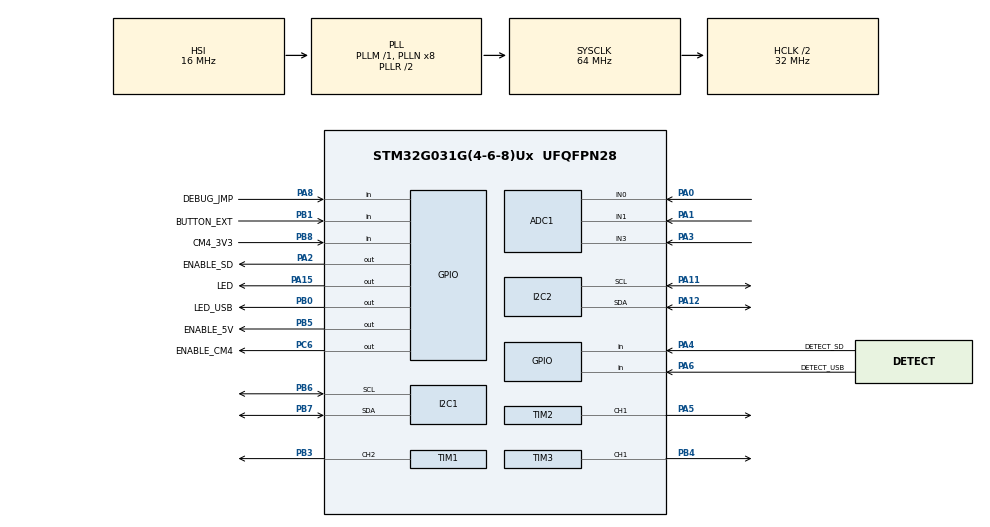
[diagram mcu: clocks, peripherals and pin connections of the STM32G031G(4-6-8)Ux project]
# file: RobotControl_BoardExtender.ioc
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ADC1.Channel-0\#ChannelRegularConversion=ADC_CHANNEL_1
ADC1.NbrOfConversionFlag=1
ADC1.Rank-0\#ChannelRegularConversion=1
ADC1.SamplingTime-0\#ChannelRegularConversion=ADC_SAMPLINGTIME_COMMON_1
ADC1.SelectedChannel=ADC_CHANNEL_0|ADC_CHANNEL_1|ADC_CHANNEL_3
ADC1.master=1
Dma.Request0=TIM3_CH1
Dma.Request1=TIM2_CH1
Dma.TIM2_CH1.1.Direction=DMA_MEMORY_TO_PERIPH
Dma.TIM2_CH1.1.EventEnable=DISABLE
Dma.TIM2_CH1.1.Instance=DMA1_Channel2
Dma.TIM2_CH1.1.MemDataAlignment=DMA_MDATAALIGN_BYTE
Dma.TIM2_CH1.1.MemInc=DMA_MINC_ENABLE
Dma.TIM2_CH1.1.Mode=DMA_NORMAL
Dma.TIM2_CH1.1.PeriphDataAlignment=DMA_PDATAALIGN_WORD
Dma.TIM2_CH1.1.PeriphInc=DMA_PINC_DISABLE
Dma.TIM2_CH1.1.Polarity=HAL_DMAMUX_REQ_GEN_RISING
Dma.TIM2_CH1.1.Priority=DMA_PRIORITY_LOW
Dma.TIM2_CH1.1.RequestNumber=1
Dma.TIM2_CH1.1.SignalID=NONE
Dma.TIM2_CH1.1.SyncEnable=DISABLE
Dma.TIM2_CH1.1.SyncPolarity=HAL_DMAMUX_SYNC_NO_EVENT
Dma.TIM2_CH1.1.SyncRequestNumber=1
Dma.TIM2_CH1.1.SyncSignalID=NONE
Dma.TIM3_CH1.0.Direction=DMA_MEMORY_TO_PERIPH
Dma.TIM3_CH1.0.EventEnable=DISABLE
Dma.TIM3_CH1.0.Instance=DMA1_Channel1
Dma.TIM3_CH1.0.MemDataAlignment=DMA_MDATAALIGN_BYTE
Dma.TIM3_CH1.0.MemInc=DMA_MINC_ENABLE
Dma.TIM3_CH1.0.Mode=DMA_NORMAL
Dma.TIM3_CH1.0.PeriphDataAlignment=DMA_PDATAALIGN_HALFWORD
Dma.TIM3_CH1.0.PeriphInc=DMA_PINC_DISABLE
Dma.TIM3_CH1.0.Polarity=HAL_DMAMUX_REQ_GEN_RISING
Dma.TIM3_CH1.0.Priority=DMA_PRIORITY_LOW
Dma.TIM3_CH1.0.RequestNumber=1
Dma.TIM3_CH1.0.SignalID=NONE
Dma.TIM3_CH1.0.SyncEnable=DISABLE
Dma.TIM3_CH1.0.SyncPolarity=HAL_DMAMUX_SYNC_NO_EVENT
Dma.TIM3_CH1.0.SyncRequestNumber=1
Dma.TIM3_CH1.0.SyncSignalID=NONE
I2C1.DualAddressMode=I2C_DUALADDRESS_ENABLE
I2C1.GeneralCallMode=I2C_GENERALCALL_DISABLE
I2C1.NoStretchMode=I2C_NOSTRETCH_DISABLE
I2C1.OwnAddress=0x01
I2C1.Timing=0x00707CBB
I2C2.OwnAddress=0x01
I2C2.Timing=0x00707CBB
Mcu.Family=STM32G0
Mcu.Name=STM32G031G(4-6-8)Ux
Mcu.Package=UFQFPN28
NVIC.DMA1_Channel1_IRQn=true\:0\:0\:false\:false\:true\:false\:true\:true
NVIC.DMA1_Channel2_3_IRQn=true\:0\:0\:false\:false\:true\:false\:true\:true
NVIC.I2C1_IRQn=true\:0\:0\:false\:false\:true\:true\:true\:true
NVIC.I2C2_IRQn=true\:0\:0\:false\:false\:true\:true\:true\:true
PA0.Mode=IN0
PA0.Signal=ADC1_IN0
PA1.Mode=IN1
PA1.Signal=ADC1_IN1
PA11\ [PA9].Mode=I2C
PA11\ [PA9].Signal=I2C2_SCL
PA12\ [PA10].Mode=I2C
PA12\ [PA10].Signal=I2C2_SDA
PA13.Mode=Serial_Wire
PA13.Signal=SYS_SWDIO
PA14-BOOT0.Mode=Serial_Wire
PA14-BOOT0.Signal=SYS_SWCLK
PA15.GPIO_Label=LED
PA15.Signal=GPIO_Output
PA2.GPIO_Label=ENABLE_SD
PA2.Signal=GPIO_Output
PA3.Mode=IN3
PA3.Signal=ADC1_IN3
PA4.GPIO_Label=DETECT_SD
PA4.Signal=GPIO_Input
PA5.GPIO_PuPd=GPIO_PULLDOWN
PA5.Signal=S_TIM2_CH1_ETR
PA6.GPIO_Label=DETECT_USB
PA6.GPIO_PuPd=GPIO_PULLUP
PA6.Signal=GPIO_Input
PA8.GPIO_Label=DEBUG_JMP
PA8.Signal=GPIO_Input
PB0.GPIO_Label=LED_USB
PB0.Signal=GPIO_Output
PB1.GPIO_Label=BUTTON_EXT
PB1.Signal=GPIO_Input
PB3.Signal=S_TIM1_CH2
PB4.Signal=S_TIM3_CH1
PB5.GPIO_Label=ENABLE_5V
PB5.Signal=GPIO_Output
PB6.Mode=I2C
PB6.Signal=I2C1_SCL
PB7.Mode=I2C
PB7.Signal=I2C1_SDA
PB8.GPIO_Label=CM4_3V3
PB8.Signal=GPIO_Input
PC6.GPIO_Label=ENABLE_CM4
PC6.GPIO_PuPd=GPIO_PULLDOWN
PC6.Signal=GPIO_Output
ProjectManager.HeapSize=0x200
ProjectManager.StackSize=0x400
ProjectManager.TargetToolchain=STM32CubeIDE
RCC.ADCFreq_Value=64000000
RCC.AHBCLKDivider=RCC_SYSCLK_DIV2
RCC.AHBFreq_Value=32000000
RCC.CortexFreq_Value=32000000
RCC.EXTERNAL_CLOCK_VALUE=12288000
RCC.HCLKFreq_Value=32000000
RCC.HSE_VALUE=8000000
RCC.HSI_VALUE=16000000
RCC.LSE_VALUE=32768
RCC.SYSCLKFreq_VALUE=64000000
RCC.SYSCLKSource=RCC_SYSCLKSOURCE_PLLCLK
RCC.VCOOutputFreq_Value=128000000
SH.S_TIM1_CH2.0=TIM1_CH2,PWM Generation2 CH2
SH.S_TIM2_CH1_ETR.0=TIM2_CH1,PWM Generation1 CH1
SH.S_TIM3_CH1.0=TIM3_CH1,PWM Generation1 CH1
TIM1.Channel-PWM\ Generation2\ CH2=TIM_CHANNEL_2
TIM1.Prescaler=5
TIM2.Channel-PWM\ Generation1\ CH1=TIM_CHANNEL_1
TIM2.Period=39
TIM3.Channel-PWM\ Generation1\ CH1=TIM_CHANNEL_1
TIM3.Period=39
board=custom

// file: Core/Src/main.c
/* USER CODE BEGIN Header */
/**
  ******************************************************************************
  * @file           : main.c
  * @brief          : Main program body
  ******************************************************************************
  * @attention
  *
  * Copyright (c) 2022 STMicroelectronics.
  * All rights reserved.
  *
  * This software is licensed under terms that can be found in the LICENSE file
  * in the root directory of this software component.
  * If no LICENSE file comes with this software, it is provided AS-IS.
  *
  ******************************************************************************
  */
/* USER CODE END Header */
#include "main.h"

ADC_HandleTypeDef hadc1;

I2C_HandleTypeDef hi2c1;
I2C_HandleTypeDef hi2c2;

TIM_HandleTypeDef htim1;
TIM_HandleTypeDef htim2;
TIM_HandleTypeDef htim3;
DMA_HandleTypeDef hdma_tim2_ch1;
DMA_HandleTypeDef hdma_tim3_ch1;

void SystemClock_Config(void);
static void MX_GPIO_Init(void);
static void MX_DMA_Init(void);
static void MX_ADC1_Init(void);
static void MX_I2C1_Init(void);
static void MX_TIM3_Init(void);
static void MX_TIM2_Init(void);
static void MX_TIM1_Init(void);
static void MX_I2C2_Init(void);

int main(void)
{

  /* MCU Configuration--------------------------------------------------------*/

  /* Reset of all peripherals, Initializes the Flash interface and the Systick. */
  HAL_Init();

  /* Configure the system clock */
  SystemClock_Config();

  /* Initialize all configured peripherals */
  MX_GPIO_Init();
  MX_DMA_Init();
  MX_ADC1_Init();
  MX_I2C1_Init();
  MX_TIM3_Init();
  MX_TIM2_Init();
  MX_TIM1_Init();
  MX_I2C2_Init();
  /* USER CODE BEGIN 2 */

  firmware_init();

  /* USER CODE END 2 */

  /* Infinite loop */
  while (1)
  {

    /* USER CODE BEGIN 3 */
	  firmware_update();
  }
  /* USER CODE END 3 */
}

void SystemClock_Config(void)
{
  RCC_OscInitTypeDef RCC_OscInitStruct = {0};
  RCC_ClkInitTypeDef RCC_ClkInitStruct = {0};

  /** Configure the main internal regulator output voltage
  */
  HAL_PWREx_ControlVoltageScaling(PWR_REGULATOR_VOLTAGE_SCALE1);

  /** Initializes the RCC Oscillators according to the specified parameters
  * in the RCC_OscInitTypeDef structure.
  */
  RCC_OscInitStruct.OscillatorType = RCC_OSCILLATORTYPE_HSI;
  RCC_OscInitStruct.HSIState = RCC_HSI_ON;
  RCC_OscInitStruct.HSIDiv = RCC_HSI_DIV1;
  RCC_OscInitStruct.HSICalibrationValue = RCC_HSICALIBRATION_DEFAULT;
  RCC_OscInitStruct.PLL.PLLState = RCC_PLL_ON;
  RCC_OscInitStruct.PLL.PLLSource = RCC_PLLSOURCE_HSI;
  RCC_OscInitStruct.PLL.PLLM = RCC_PLLM_DIV1;
  RCC_OscInitStruct.PLL.PLLN = 8;
  RCC_OscInitStruct.PLL.PLLP = RCC_PLLP_DIV2;
  RCC_OscInitStruct.PLL.PLLQ = RCC_PLLQ_DIV2;
  RCC_OscInitStruct.PLL.PLLR = RCC_PLLR_DIV2;
  if (HAL_RCC_OscConfig(&RCC_OscInitStruct) != HAL_OK)
  {
    Error_Handler();
  }

  /** Initializes the CPU, AHB and APB buses clocks
  */
  RCC_ClkInitStruct.ClockType = RCC_CLOCKTYPE_HCLK|RCC_CLOCKTYPE_SYSCLK
                              |RCC_CLOCKTYPE_PCLK1;
  RCC_ClkInitStruct.SYSCLKSource = RCC_SYSCLKSOURCE_PLLCLK;
  RCC_ClkInitStruct.AHBCLKDivider = RCC_SYSCLK_DIV2;
  RCC_ClkInitStruct.APB1CLKDivider = RCC_HCLK_DIV1;

  if (HAL_RCC_ClockConfig(&RCC_ClkInitStruct, FLASH_LATENCY_1) != HAL_OK)
  {
    Error_Handler();
  }
}

static void MX_ADC1_Init(void)
{

  ADC_ChannelConfTypeDef sConfig = {0};

  /** Configure the global features of the ADC (Clock, Resolution, Data Alignment and number of conversion)
  */
  hadc1.Instance = ADC1;
  hadc1.Init.ClockPrescaler = ADC_CLOCK_SYNC_PCLK_DIV2;
  hadc1.Init.Resolution = ADC_RESOLUTION_12B;
  hadc1.Init.DataAlign = ADC_DATAALIGN_RIGHT;
  hadc1.Init.ScanConvMode = ADC_SCAN_DISABLE;
  hadc1.Init.EOCSelection = ADC_EOC_SINGLE_CONV;
  hadc1.Init.LowPowerAutoWait = DISABLE;
  hadc1.Init.LowPowerAutoPowerOff = DISABLE;
  hadc1.Init.ContinuousConvMode = DISABLE;
  hadc1.Init.NbrOfConversion = 1;
  hadc1.Init.DiscontinuousConvMode = DISABLE;
  hadc1.Init.ExternalTrigConv = ADC_SOFTWARE_START;
  hadc1.Init.ExternalTrigConvEdge = ADC_EXTERNALTRIGCONVEDGE_NONE;
  hadc1.Init.DMAContinuousRequests = DISABLE;
  hadc1.Init.Overrun = ADC_OVR_DATA_PRESERVED;
  hadc1.Init.SamplingTimeCommon1 = ADC_SAMPLETIME_1CYCLE_5;
  hadc1.Init.SamplingTimeCommon2 = ADC_SAMPLETIME_1CYCLE_5;
  hadc1.Init.OversamplingMode = DISABLE;
  hadc1.Init.TriggerFrequencyMode = ADC_TRIGGER_FREQ_HIGH;
  if (HAL_ADC_Init(&hadc1) != HAL_OK)
  {
    Error_Handler();
  }

  /** Configure Regular Channel
  */
  sConfig.Channel = ADC_CHANNEL_1;
  sConfig.Rank = ADC_REGULAR_RANK_1;
  sConfig.SamplingTime = ADC_SAMPLINGTIME_COMMON_1;
  if (HAL_ADC_ConfigChannel(&hadc1, &sConfig) != HAL_OK)
  {
    Error_Handler();
  }

}

static void MX_I2C1_Init(void)
{

  hi2c1.Instance = I2C1;
  hi2c1.Init.Timing = 0x00707CBB;
  hi2c1.Init.OwnAddress1 = 2;
  hi2c1.Init.AddressingMode = I2C_ADDRESSINGMODE_7BIT;
  hi2c1.Init.DualAddressMode = I2C_DUALADDRESS_ENABLE;
  hi2c1.Init.OwnAddress2 = 0;
  hi2c1.Init.OwnAddress2Masks = I2C_OA2_NOMASK;
  hi2c1.Init.GeneralCallMode = I2C_GENERALCALL_DISABLE;
  hi2c1.Init.NoStretchMode = I2C_NOSTRETCH_DISABLE;
  if (HAL_I2C_Init(&hi2c1) != HAL_OK)
  {
    Error_Handler();
  }

  /** Configure Analogue filter
  */
  if (HAL_I2CEx_ConfigAnalogFilter(&hi2c1, I2C_ANALOGFILTER_ENABLE) != HAL_OK)
  {
    Error_Handler();
  }

  /** Configure Digital filter
  */
  if (HAL_I2CEx_ConfigDigitalFilter(&hi2c1, 0) != HAL_OK)
  {
    Error_Handler();
  }

}

static void MX_I2C2_Init(void)
{

  hi2c2.Instance = I2C2;
  hi2c2.Init.Timing = 0x00707CBB;
  hi2c2.Init.OwnAddress1 = 2;
  hi2c2.Init.AddressingMode = I2C_ADDRESSINGMODE_7BIT;
  hi2c2.Init.DualAddressMode = I2C_DUALADDRESS_DISABLE;
  hi2c2.Init.OwnAddress2 = 0;
  hi2c2.Init.OwnAddress2Masks = I2C_OA2_NOMASK;
  hi2c2.Init.GeneralCallMode = I2C_GENERALCALL_DISABLE;
  hi2c2.Init.NoStretchMode = I2C_NOSTRETCH_DISABLE;
  if (HAL_I2C_Init(&hi2c2) != HAL_OK)
  {
    Error_Handler();
  }

  /** Configure Analogue filter
  */
  if (HAL_I2CEx_ConfigAnalogFilter(&hi2c2, I2C_ANALOGFILTER_ENABLE) != HAL_OK)
  {
    Error_Handler();
  }

  /** Configure Digital filter
  */
  if (HAL_I2CEx_ConfigDigitalFilter(&hi2c2, 0) != HAL_OK)
  {
    Error_Handler();
  }

}

static void MX_TIM1_Init(void)
{

  TIM_MasterConfigTypeDef sMasterConfig = {0};
  TIM_OC_InitTypeDef sConfigOC = {0};
  TIM_BreakDeadTimeConfigTypeDef sBreakDeadTimeConfig = {0};

  htim1.Instance = TIM1;
  htim1.Init.Prescaler = 5;
  htim1.Init.CounterMode = TIM_COUNTERMODE_UP;
  htim1.Init.Period = 65535;
  htim1.Init.ClockDivision = TIM_CLOCKDIVISION_DIV1;
  htim1.Init.RepetitionCounter = 0;
  htim1.Init.AutoReloadPreload = TIM_AUTORELOAD_PRELOAD_DISABLE;
  if (HAL_TIM_PWM_Init(&htim1) != HAL_OK)
  {
    Error_Handler();
  }
  sMasterConfig.MasterOutputTrigger = TIM_TRGO_RESET;
  sMasterConfig.MasterOutputTrigger2 = TIM_TRGO2_RESET;
  sMasterConfig.MasterSlaveMode = TIM_MASTERSLAVEMODE_DISABLE;
  if (HAL_TIMEx_MasterConfigSynchronization(&htim1, &sMasterConfig) != HAL_OK)
  {
    Error_Handler();
  }
  sConfigOC.OCMode = TIM_OCMODE_PWM1;
  sConfigOC.Pulse = 0;
  sConfigOC.OCPolarity = TIM_OCPOLARITY_HIGH;
  sConfigOC.OCNPolarity = TIM_OCNPOLARITY_HIGH;
  sConfigOC.OCFastMode = TIM_OCFAST_DISABLE;
  sConfigOC.OCIdleState = TIM_OCIDLESTATE_RESET;
  sConfigOC.OCNIdleState = TIM_OCNIDLESTATE_RESET;
  if (HAL_TIM_PWM_ConfigChannel(&htim1, &sConfigOC, TIM_CHANNEL_2) != HAL_OK)
  {
    Error_Handler();
  }
  sBreakDeadTimeConfig.OffStateRunMode = TIM_OSSR_DISABLE;
  sBreakDeadTimeConfig.OffStateIDLEMode = TIM_OSSI_DISABLE;
  sBreakDeadTimeConfig.LockLevel = TIM_LOCKLEVEL_OFF;
  sBreakDeadTimeConfig.DeadTime = 0;
  sBreakDeadTimeConfig.BreakState = TIM_BREAK_DISABLE;
  sBreakDeadTimeConfig.BreakPolarity = TIM_BREAKPOLARITY_HIGH;
  sBreakDeadTimeConfig.BreakFilter = 0;
  sBreakDeadTimeConfig.BreakAFMode = TIM_BREAK_AFMODE_INPUT;
  sBreakDeadTimeConfig.Break2State = TIM_BREAK2_DISABLE;
  sBreakDeadTimeConfig.Break2Polarity = TIM_BREAK2POLARITY_HIGH;
  sBreakDeadTimeConfig.Break2Filter = 0;
  sBreakDeadTimeConfig.Break2AFMode = TIM_BREAK_AFMODE_INPUT;
  sBreakDeadTimeConfig.AutomaticOutput = TIM_AUTOMATICOUTPUT_DISABLE;
  if (HAL_TIMEx_ConfigBreakDeadTime(&htim1, &sBreakDeadTimeConfig) != HAL_OK)
  {
    Error_Handler();
  }
  HAL_TIM_MspPostInit(&htim1);

}

static void MX_TIM2_Init(void)
{

  TIM_MasterConfigTypeDef sMasterConfig = {0};
  TIM_OC_InitTypeDef sConfigOC = {0};

  htim2.Instance = TIM2;
  htim2.Init.Prescaler = 0;
  htim2.Init.CounterMode = TIM_COUNTERMODE_UP;
  htim2.Init.Period = 39;
  htim2.Init.ClockDivision = TIM_CLOCKDIVISION_DIV1;
  htim2.Init.AutoReloadPreload = TIM_AUTORELOAD_PRELOAD_DISABLE;
  if (HAL_TIM_PWM_Init(&htim2) != HAL_OK)
  {
    Error_Handler();
  }
  sMasterConfig.MasterOutputTrigger = TIM_TRGO_RESET;
  sMasterConfig.MasterSlaveMode = TIM_MASTERSLAVEMODE_DISABLE;
  if (HAL_TIMEx_MasterConfigSynchronization(&htim2, &sMasterConfig) != HAL_OK)
  {
    Error_Handler();
  }
  sConfigOC.OCMode = TIM_OCMODE_PWM1;
  sConfigOC.Pulse = 0;
  sConfigOC.OCPolarity = TIM_OCPOLARITY_HIGH;
  sConfigOC.OCFastMode = TIM_OCFAST_DISABLE;
  if (HAL_TIM_PWM_ConfigChannel(&htim2, &sConfigOC, TIM_CHANNEL_1) != HAL_OK)
  {
    Error_Handler();
  }
  HAL_TIM_MspPostInit(&htim2);

}

static void MX_TIM3_Init(void)
{

  TIM_MasterConfigTypeDef sMasterConfig = {0};
  TIM_OC_InitTypeDef sConfigOC = {0};

  htim3.Instance = TIM3;
  htim3.Init.Prescaler = 0;
  htim3.Init.CounterMode = TIM_COUNTERMODE_UP;
  htim3.Init.Period = 39;
  htim3.Init.ClockDivision = TIM_CLOCKDIVISION_DIV1;
  htim3.Init.AutoReloadPreload = TIM_AUTORELOAD_PRELOAD_DISABLE;
  if (HAL_TIM_PWM_Init(&htim3) != HAL_OK)
  {
    Error_Handler();
  }
  sMasterConfig.MasterOutputTrigger = TIM_TRGO_RESET;
  sMasterConfig.MasterSlaveMode = TIM_MASTERSLAVEMODE_DISABLE;
  if (HAL_TIMEx_MasterConfigSynchronization(&htim3, &sMasterConfig) != HAL_OK)
  {
    Error_Handler();
  }
  sConfigOC.OCMode = TIM_OCMODE_PWM1;
  sConfigOC.Pulse = 0;
  sConfigOC.OCPolarity = TIM_OCPOLARITY_HIGH;
  sConfigOC.OCFastMode = TIM_OCFAST_DISABLE;
  if (HAL_TIM_PWM_ConfigChannel(&htim3, &sConfigOC, TIM_CHANNEL_1) != HAL_OK)
  {
    Error_Handler();
  }
  HAL_TIM_MspPostInit(&htim3);

}

static void MX_DMA_Init(void)
{

  /* DMA controller clock enable */
  __HAL_RCC_DMA1_CLK_ENABLE();

  /* DMA interrupt init */
  /* DMA1_Channel1_IRQn interrupt configuration */
  HAL_NVIC_SetPriority(DMA1_Channel1_IRQn, 0, 0);
  HAL_NVIC_EnableIRQ(DMA1_Channel1_IRQn);
  /* DMA1_Channel2_3_IRQn interrupt configuration */
  HAL_NVIC_SetPriority(DMA1_Channel2_3_IRQn, 0, 0);
  HAL_NVIC_EnableIRQ(DMA1_Channel2_3_IRQn);

}

static void MX_GPIO_Init(void)
{
  GPIO_InitTypeDef GPIO_InitStruct = {0};

  /* GPIO Ports Clock Enable */
  __HAL_RCC_GPIOA_CLK_ENABLE();
  __HAL_RCC_GPIOB_CLK_ENABLE();
  __HAL_RCC_GPIOC_CLK_ENABLE();

  /*Configure GPIO pin Output Level */
  HAL_GPIO_WritePin(GPIOA, ENABLE_SD_Pin|LED_Pin, GPIO_PIN_RESET);

  /*Configure GPIO pin Output Level */
  HAL_GPIO_WritePin(GPIOB, LED_USB_Pin|ENABLE_5V_Pin, GPIO_PIN_RESET);

  /*Configure GPIO pin Output Level */
  HAL_GPIO_WritePin(ENABLE_CM4_GPIO_Port, ENABLE_CM4_Pin, GPIO_PIN_RESET);

  /*Configure GPIO pins : ENABLE_SD_Pin LED_Pin */
  GPIO_InitStruct.Pin = ENABLE_SD_Pin|LED_Pin;
  GPIO_InitStruct.Mode = GPIO_MODE_OUTPUT_PP;
  GPIO_InitStruct.Pull = GPIO_NOPULL;
  GPIO_InitStruct.Speed = GPIO_SPEED_FREQ_LOW;
  HAL_GPIO_Init(GPIOA, &GPIO_InitStruct);

  /*Configure GPIO pins : DETECT_SD_Pin DEBUG_JMP_Pin */
  GPIO_InitStruct.Pin = DETECT_SD_Pin|DEBUG_JMP_Pin;
  GPIO_InitStruct.Mode = GPIO_MODE_INPUT;
  GPIO_InitStruct.Pull = GPIO_NOPULL;
  HAL_GPIO_Init(GPIOA, &GPIO_InitStruct);

  /*Configure GPIO pin : DETECT_USB_Pin */
  GPIO_InitStruct.Pin = DETECT_USB_Pin;
  GPIO_InitStruct.Mode = GPIO_MODE_INPUT;
  GPIO_InitStruct.Pull = GPIO_PULLUP;
  HAL_GPIO_Init(DETECT_USB_GPIO_Port, &GPIO_InitStruct);

  /*Configure GPIO pins : LED_USB_Pin ENABLE_5V_Pin */
  GPIO_InitStruct.Pin = LED_USB_Pin|ENABLE_5V_Pin;
  GPIO_InitStruct.Mode = GPIO_MODE_OUTPUT_PP;
  GPIO_InitStruct.Pull = GPIO_NOPULL;
  GPIO_InitStruct.Speed = GPIO_SPEED_FREQ_LOW;
  HAL_GPIO_Init(GPIOB, &GPIO_InitStruct);

  /*Configure GPIO pins : BUTTON_EXT_Pin CM4_3V3_Pin */
  GPIO_InitStruct.Pin = BUTTON_EXT_Pin|CM4_3V3_Pin;
  GPIO_InitStruct.Mode = GPIO_MODE_INPUT;
  GPIO_InitStruct.Pull = GPIO_NOPULL;
  HAL_GPIO_Init(GPIOB, &GPIO_InitStruct);

  /*Configure GPIO pin : ENABLE_CM4_Pin */
  GPIO_InitStruct.Pin = ENABLE_CM4_Pin;
  GPIO_InitStruct.Mode = GPIO_MODE_OUTPUT_PP;
  GPIO_InitStruct.Pull = GPIO_PULLDOWN;
  GPIO_InitStruct.Speed = GPIO_SPEED_FREQ_LOW;
  HAL_GPIO_Init(ENABLE_CM4_GPIO_Port, &GPIO_InitStruct);

}

void Error_Handler(void)
{
  __disable_irq();
  while (1)
  {
  }
}
